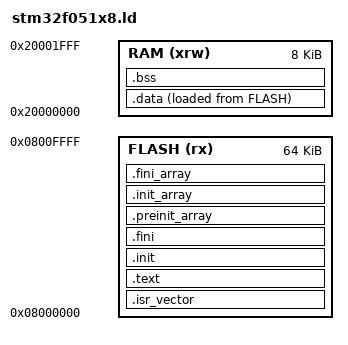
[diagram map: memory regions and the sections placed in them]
ENTRY(Reset_Handler)

_estack = ORIGIN(RAM) + LENGTH(RAM);

MEMORY
{
    FLASH (rx)  : ORIGIN = 0x08000000, LENGTH = 64K
    RAM   (xrw) : ORIGIN = 0x20000000, LENGTH = 8K
}

SECTIONS
{
    .isr_vector :
    {
        . = ALIGN(4);
        KEEP(*(.isr_vector))
        . = ALIGN(4);
    } > FLASH

    .text :
    {
        . = ALIGN(4);
        *(.text)
        *(.text*)
        *(.rodata)
        *(.rodata*)
        . = ALIGN(4);
        _etext = .;
    } > FLASH

    /* C runtime initialization and finalization code */
    .init :
    {
        KEEP(*(.init))
    } > FLASH

    .fini :
    {
        KEEP(*(.fini))
    } > FLASH

    /* C++ constructors / C runtime initialization arrays */
    .preinit_array :
    {
        . = ALIGN(4);
        PROVIDE_HIDDEN(__preinit_array_start = .);
        KEEP(*(.preinit_array))
        PROVIDE_HIDDEN(__preinit_array_end = .);
    } > FLASH

    .init_array :
    {
        . = ALIGN(4);
        PROVIDE_HIDDEN(__init_array_start = .);
        KEEP(*(SORT_BY_INIT_PRIORITY(.init_array.*)))
        KEEP(*(.init_array))
        PROVIDE_HIDDEN(__init_array_end = .);
    } > FLASH

    .fini_array :
    {
        . = ALIGN(4);
        PROVIDE_HIDDEN(__fini_array_start = .);
        KEEP(*(SORT_BY_INIT_PRIORITY(.fini_array.*)))
        KEEP(*(.fini_array))
        PROVIDE_HIDDEN(__fini_array_end = .);
    } > FLASH

    _sidata = LOADADDR(.data);

    .data :
    {
        . = ALIGN(4);
        _sdata = .;
        *(.data)
        *(.data*)
        . = ALIGN(4);
        _edata = .;
    } > RAM AT > FLASH

    .bss :
    {
        . = ALIGN(4);
        _sbss = .;
        *(.bss)
        *(.bss*)
        *(COMMON)
        . = ALIGN(4);
        _ebss = .;
    } > RAM

    . = ALIGN(8);
    _end = .;
}
